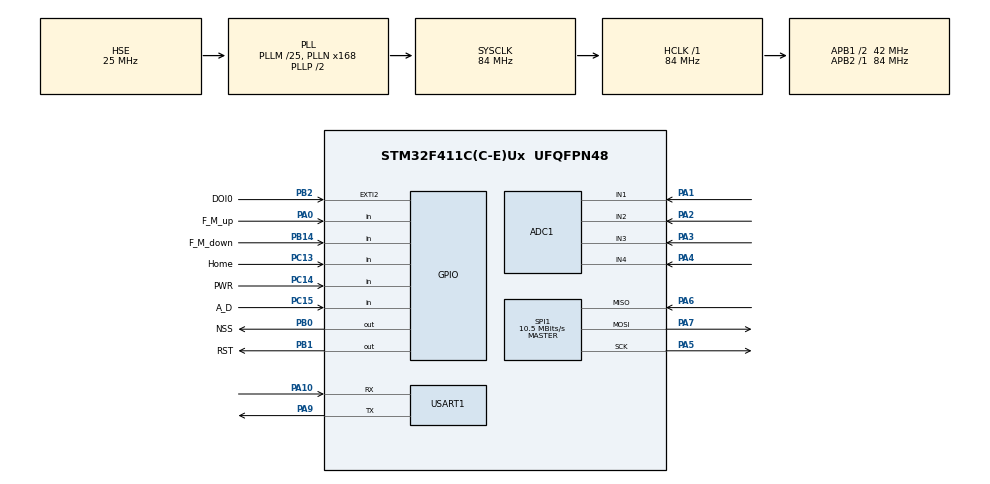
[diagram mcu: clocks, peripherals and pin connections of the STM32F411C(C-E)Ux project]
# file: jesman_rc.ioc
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ADC1.Channel-0\#ChannelRegularConversion=ADC_CHANNEL_1
ADC1.Channel-1\#ChannelRegularConversion=ADC_CHANNEL_2
ADC1.Channel-2\#ChannelRegularConversion=ADC_CHANNEL_3
ADC1.Channel-3\#ChannelRegularConversion=ADC_CHANNEL_4
ADC1.ContinuousConvMode=ENABLE
ADC1.DMAContinuousRequests=ENABLE
ADC1.EnableAnalogWatchDog=false
ADC1.InjNumberOfConversion=0
ADC1.NbrOfConversion=4
ADC1.NbrOfConversionFlag=1
ADC1.Rank-0\#ChannelRegularConversion=1
ADC1.Rank-1\#ChannelRegularConversion=2
ADC1.Rank-2\#ChannelRegularConversion=3
ADC1.Rank-3\#ChannelRegularConversion=4
ADC1.SamplingTime-0\#ChannelRegularConversion=ADC_SAMPLETIME_480CYCLES
ADC1.SamplingTime-1\#ChannelRegularConversion=ADC_SAMPLETIME_480CYCLES
ADC1.SamplingTime-2\#ChannelRegularConversion=ADC_SAMPLETIME_480CYCLES
ADC1.SamplingTime-3\#ChannelRegularConversion=ADC_SAMPLETIME_480CYCLES
ADC1.master=1
Dma.ADC1.0.Direction=DMA_PERIPH_TO_MEMORY
Dma.ADC1.0.FIFOMode=DMA_FIFOMODE_DISABLE
Dma.ADC1.0.Instance=DMA2_Stream0
Dma.ADC1.0.MemDataAlignment=DMA_MDATAALIGN_HALFWORD
Dma.ADC1.0.MemInc=DMA_MINC_ENABLE
Dma.ADC1.0.Mode=DMA_CIRCULAR
Dma.ADC1.0.PeriphDataAlignment=DMA_PDATAALIGN_HALFWORD
Dma.ADC1.0.PeriphInc=DMA_PINC_DISABLE
Dma.ADC1.0.Priority=DMA_PRIORITY_HIGH
Dma.Request0=ADC1
Mcu.Family=STM32F4
Mcu.Name=STM32F411C(C-E)Ux
Mcu.Package=UFQFPN48
NVIC.ADC_IRQn=true\:1\:0\:true\:false\:true\:true\:true\:true
NVIC.DMA2_Stream0_IRQn=true\:0\:0\:false\:false\:true\:false\:true\:true
NVIC.PriorityGroup=NVIC_PRIORITYGROUP_4
PA0-WKUP.GPIO_Label=F_M_up
PA0-WKUP.GPIO_PuPd=GPIO_PULLDOWN
PA0-WKUP.Signal=GPIO_Input
PA1.Signal=ADCx_IN1
PA10.Mode=Asynchronous
PA10.Signal=USART1_RX
PA13.Mode=Serial_Wire
PA13.Signal=SYS_JTMS-SWDIO
PA14.Mode=Serial_Wire
PA14.Signal=SYS_JTCK-SWCLK
PA2.Signal=ADCx_IN2
PA3.Signal=ADCx_IN3
PA4.Signal=ADCx_IN4
PA5.Mode=Full_Duplex_Master
PA5.Signal=SPI1_SCK
PA6.Mode=Full_Duplex_Master
PA6.Signal=SPI1_MISO
PA7.Mode=Full_Duplex_Master
PA7.Signal=SPI1_MOSI
PA9.Mode=Asynchronous
PA9.Signal=USART1_TX
PB0.GPIO_Label=NSS
PB0.PinState=GPIO_PIN_SET
PB0.Signal=GPIO_Output
PB1.GPIO_Label=RST
PB1.PinState=GPIO_PIN_SET
PB1.Signal=GPIO_Output
PB14.GPIO_Label=F_M_down
PB14.GPIO_PuPd=GPIO_PULLDOWN
PB14.Signal=GPIO_Input
PB2.GPIO_Label=DOI0
PB2.Signal=GPXTI2
PC13-ANTI_TAMP.GPIO_Label=Home
PC13-ANTI_TAMP.GPIO_PuPd=GPIO_PULLDOWN
PC13-ANTI_TAMP.Signal=GPIO_Input
PC14-OSC32_IN.GPIO_Label=PWR
PC14-OSC32_IN.GPIO_PuPd=GPIO_PULLDOWN
PC14-OSC32_IN.Signal=GPIO_Input
PC15-OSC32_OUT.GPIO_Label=A_D
PC15-OSC32_OUT.GPIO_PuPd=GPIO_PULLDOWN
PC15-OSC32_OUT.Signal=GPIO_Input
PH0\ -\ OSC_IN.Mode=HSE-External-Oscillator
PH0\ -\ OSC_IN.Signal=RCC_OSC_IN
PH1\ -\ OSC_OUT.Mode=HSE-External-Oscillator
PH1\ -\ OSC_OUT.Signal=RCC_OSC_OUT
ProjectManager.HeapSize=0x200
ProjectManager.StackSize=0x400
ProjectManager.TargetToolchain=STM32CubeIDE
RCC.48MHZClocksFreq_Value=42000000
RCC.AHBFreq_Value=84000000
RCC.APB1CLKDivider=RCC_HCLK_DIV2
RCC.APB1Freq_Value=42000000
RCC.APB1TimFreq_Value=84000000
RCC.APB2Freq_Value=84000000
RCC.APB2TimFreq_Value=84000000
RCC.CortexFreq_Value=84000000
RCC.HCLKFreq_Value=84000000
RCC.HSE_VALUE=25000000
RCC.HSI_VALUE=16000000
RCC.LSE_VALUE=32768
RCC.PLLM=25
RCC.PLLN=168
RCC.PLLSourceVirtual=RCC_PLLSOURCE_HSE
RCC.SYSCLKFreq_VALUE=84000000
RCC.SYSCLKSource=RCC_SYSCLKSOURCE_PLLCLK
RCC.VCOOutputFreq_Value=168000000
SH.ADCx_IN1.0=ADC1_IN1,IN1
SH.ADCx_IN2.0=ADC1_IN2,IN2
SH.ADCx_IN3.0=ADC1_IN3,IN3
SH.ADCx_IN4.0=ADC1_IN4,IN4
SPI1.BaudRatePrescaler=SPI_BAUDRATEPRESCALER_8
SPI1.CRCCalculation=SPI_CRCCALCULATION_ENABLE
SPI1.CalculateBaudRate=10.5 MBits/s
SPI1.Direction=SPI_DIRECTION_2LINES
SPI1.Mode=SPI_MODE_MASTER
SPI1.VirtualType=VM_MASTER
USART1.VirtualMode=VM_ASYNC
board=custom

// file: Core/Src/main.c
/* USER CODE BEGIN Header */
/**
  ******************************************************************************
  * @file           : main.c
  * @brief          : Main program body
  ******************************************************************************
  * @attention
  *
  * Copyright (c) 2025 STMicroelectronics.
  * All rights reserved.
  *
  * This software is licensed under terms that can be found in the LICENSE file
  * in the root directory of this software component.
  * If no LICENSE file comes with this software, it is provided AS-IS.
  *
  ******************************************************************************
  */
/* USER CODE END Header */
#include "main.h"

/* USER CODE BEGIN Includes */
#include "joystick.h"
#include "joystick_cfg.h"
#include "calib_button.h"

/* USER CODE END Includes */

/* USER CODE BEGIN PD */
uint16_t JoyStick1_XY[2] = {0};
uint16_t JoyStick2_XY[2] = {0};

/* USER CODE END PD */

ADC_HandleTypeDef hadc1;
DMA_HandleTypeDef hdma_adc1;

SPI_HandleTypeDef hspi1;

//UART_HandleTypeDef huart1;

void SystemClock_Config(void);
static void MX_GPIO_Init(void);
static void MX_DMA_Init(void);
static void MX_SPI1_Init(void);
static void MX_ADC1_Init(void);
static void MX_USART1_UART_Init(void);

int main(void)
{

  /* MCU Configuration--------------------------------------------------------*/

  /* Reset of all peripherals, Initializes the Flash interface and the Systick. */
  HAL_Init();

  /* Configure the system clock */
  SystemClock_Config();

  /* Initialize all configured peripherals */
  MX_GPIO_Init();
  MX_DMA_Init();
  MX_SPI1_Init();
  MX_ADC1_Init();
  MX_USART1_UART_Init();
  JoyStick_Init(JOYSTICK_INST_1);
  JoyStick_Init(JOYSTICK_INST_2);
  Joystick_Calibrate();

  /* Infinite loop */
  while (1)
  {
	  calib_button_state();
	  JoyStick_Read(JOYSTICK_INST_1, JoyStick1_XY[2]);
	  JoyStick_Read(JOYSTICK_INST_2, JoyStick2_XY[2]);

	  sprintf(MSG1, "%d,%d\r\n", JoyStick1_XY[0], JoyStick1_XY[1]);
	  sprintf(MSG2, "%d,%d\r\n", JoyStick2_XY[0], JoyStick2_XY[1]);
	  HAL_UART_Transmit(&huart1, MSG1, sizeof(MSG1), 100);
	  HAL_Delay(100);

  }
}

void SystemClock_Config(void)
{
  RCC_OscInitTypeDef RCC_OscInitStruct = {0};
  RCC_ClkInitTypeDef RCC_ClkInitStruct = {0};

  /** Configure the main internal regulator output voltage
  */
  __HAL_RCC_PWR_CLK_ENABLE();
  __HAL_PWR_VOLTAGESCALING_CONFIG(PWR_REGULATOR_VOLTAGE_SCALE1);

  /** Initializes the RCC Oscillators according to the specified parameters
  * in the RCC_OscInitTypeDef structure.
  */
  RCC_OscInitStruct.OscillatorType = RCC_OSCILLATORTYPE_HSE;
  RCC_OscInitStruct.HSEState = RCC_HSE_ON;
  RCC_OscInitStruct.PLL.PLLState = RCC_PLL_ON;
  RCC_OscInitStruct.PLL.PLLSource = RCC_PLLSOURCE_HSE;
  RCC_OscInitStruct.PLL.PLLM = 25;
  RCC_OscInitStruct.PLL.PLLN = 168;
  RCC_OscInitStruct.PLL.PLLP = RCC_PLLP_DIV2;
  RCC_OscInitStruct.PLL.PLLQ = 4;
  if (HAL_RCC_OscConfig(&RCC_OscInitStruct) != HAL_OK)
  {
    Error_Handler();
  }

  /** Initializes the CPU, AHB and APB buses clocks
  */
  RCC_ClkInitStruct.ClockType = RCC_CLOCKTYPE_HCLK|RCC_CLOCKTYPE_SYSCLK
                              |RCC_CLOCKTYPE_PCLK1|RCC_CLOCKTYPE_PCLK2;
  RCC_ClkInitStruct.SYSCLKSource = RCC_SYSCLKSOURCE_PLLCLK;
  RCC_ClkInitStruct.AHBCLKDivider = RCC_SYSCLK_DIV1;
  RCC_ClkInitStruct.APB1CLKDivider = RCC_HCLK_DIV2;
  RCC_ClkInitStruct.APB2CLKDivider = RCC_HCLK_DIV1;

  if (HAL_RCC_ClockConfig(&RCC_ClkInitStruct, FLASH_LATENCY_2) != HAL_OK)
  {
    Error_Handler();
  }
}

/**
  * @brief ADC1 Initialization Function
  * @param None
  * @retval None
static void MX_ADC1_Init(void)
{

  //ADC_ChannelConfTypeDef sConfig = {0};

  /** Configure the global features of the ADC (Clock, Resolution, Data Alignment and number of conversion)
  hadc1.Instance = ADC1;
  hadc1.Init.ClockPrescaler = ADC_CLOCK_SYNC_PCLK_DIV4;
  hadc1.Init.Resolution = ADC_RESOLUTION_12B;
  hadc1.Init.ScanConvMode = ENABLE;
  hadc1.Init.ContinuousConvMode = ENABLE;
  hadc1.Init.DiscontinuousConvMode = DISABLE;
  hadc1.Init.ExternalTrigConvEdge = ADC_EXTERNALTRIGCONVEDGE_NONE;
  hadc1.Init.ExternalTrigConv = ADC_SOFTWARE_START;
  hadc1.Init.DataAlign = ADC_DATAALIGN_RIGHT;
  hadc1.Init.NbrOfConversion = 4;
  hadc1.Init.DMAContinuousRequests = ENABLE;
  hadc1.Init.EOCSelection = ADC_EOC_SINGLE_CONV;
  if (HAL_ADC_Init(&hadc1) != HAL_OK)
  {
    Error_Handler();
  }

  /** Configure for the selected ADC regular channel its corresponding rank in the sequencer and its sample time.
  sConfig.Channel = ADC_CHANNEL_1;
  sConfig.Rank = 1;
  sConfig.SamplingTime = ADC_SAMPLETIME_480CYCLES;
  if (HAL_ADC_ConfigChannel(&hadc1, &sConfig) != HAL_OK)
  {
    Error_Handler();
  }

  /** Configure for the selected ADC regular channel its corresponding rank in the sequencer and its sample time.
  sConfig.Channel = ADC_CHANNEL_2;
  sConfig.Rank = 2;
  if (HAL_ADC_ConfigChannel(&hadc1, &sConfig) != HAL_OK)
  {
    Error_Handler();
  }

  /** Configure for the selected ADC regular channel its corresponding rank in the sequencer and its sample time.
  sConfig.Channel = ADC_CHANNEL_3;
  sConfig.Rank = 3;
  if (HAL_ADC_ConfigChannel(&hadc1, &sConfig) != HAL_OK)
  {
    Error_Handler();
  }

  /** Configure for the selected ADC regular channel its corresponding rank in the sequencer and its sample time.
  sConfig.Channel = ADC_CHANNEL_4;
  sConfig.Rank = 4;
  if (HAL_ADC_ConfigChannel(&hadc1, &sConfig) != HAL_OK)
  {
    Error_Handler();
  }
  /* USER CODE BEGIN ADC1_Init 2 */

  /* USER CODE END ADC1_Init 2

}
*/

static void MX_SPI1_Init(void)
{

  /* SPI1 parameter configuration*/
  hspi1.Instance = SPI1;
  hspi1.Init.Mode = SPI_MODE_MASTER;
  hspi1.Init.Direction = SPI_DIRECTION_2LINES;
  hspi1.Init.DataSize = SPI_DATASIZE_8BIT;
  hspi1.Init.CLKPolarity = SPI_POLARITY_LOW;
  hspi1.Init.CLKPhase = SPI_PHASE_1EDGE;
  hspi1.Init.NSS = SPI_NSS_SOFT;
  hspi1.Init.BaudRatePrescaler = SPI_BAUDRATEPRESCALER_8;
  hspi1.Init.FirstBit = SPI_FIRSTBIT_MSB;
  hspi1.Init.TIMode = SPI_TIMODE_DISABLE;
  hspi1.Init.CRCCalculation = SPI_CRCCALCULATION_ENABLE;
  hspi1.Init.CRCPolynomial = 10;
  if (HAL_SPI_Init(&hspi1) != HAL_OK)
  {
    Error_Handler();
  }

}

static void MX_USART1_UART_Init(void)
{

  huart1.Instance = USART1;
  huart1.Init.BaudRate = 115200;
  huart1.Init.WordLength = UART_WORDLENGTH_8B;
  huart1.Init.StopBits = UART_STOPBITS_1;
  huart1.Init.Parity = UART_PARITY_NONE;
  huart1.Init.Mode = UART_MODE_TX_RX;
  huart1.Init.HwFlowCtl = UART_HWCONTROL_NONE;
  huart1.Init.OverSampling = UART_OVERSAMPLING_16;
  if (HAL_UART_Init(&huart1) != HAL_OK)
  {
    Error_Handler();
  }

}

static void MX_DMA_Init(void)
{

  /* DMA controller clock enable */
  __HAL_RCC_DMA2_CLK_ENABLE();

  /* DMA interrupt init */
  /* DMA2_Stream0_IRQn interrupt configuration */
  HAL_NVIC_SetPriority(DMA2_Stream0_IRQn, 0, 0);
  HAL_NVIC_EnableIRQ(DMA2_Stream0_IRQn);

}

static void MX_GPIO_Init(void)
{
  GPIO_InitTypeDef GPIO_InitStruct = {0};

  /* GPIO Ports Clock Enable */
  __HAL_RCC_GPIOC_CLK_ENABLE();
  __HAL_RCC_GPIOH_CLK_ENABLE();
  __HAL_RCC_GPIOA_CLK_ENABLE();
  __HAL_RCC_GPIOB_CLK_ENABLE();

  /*Configure GPIO pin Output Level */
  HAL_GPIO_WritePin(GPIOB, NSS_Pin|RST_Pin, GPIO_PIN_SET);

  /*Configure GPIO pins : Home_Pin PWR_Pin A_D_Pin */
  GPIO_InitStruct.Pin = Home_Pin|PWR_Pin|A_D_Pin;
  GPIO_InitStruct.Mode = GPIO_MODE_INPUT;
  GPIO_InitStruct.Pull = GPIO_PULLDOWN;
  HAL_GPIO_Init(GPIOC, &GPIO_InitStruct);

  /*Configure GPIO pin : F_M_up_Pin */
  GPIO_InitStruct.Pin = F_M_up_Pin;
  GPIO_InitStruct.Mode = GPIO_MODE_INPUT;
  GPIO_InitStruct.Pull = GPIO_PULLDOWN;
  HAL_GPIO_Init(F_M_up_GPIO_Port, &GPIO_InitStruct);

  /*Configure GPIO pins : NSS_Pin RST_Pin */
  GPIO_InitStruct.Pin = NSS_Pin|RST_Pin;
  GPIO_InitStruct.Mode = GPIO_MODE_OUTPUT_PP;
  GPIO_InitStruct.Pull = GPIO_NOPULL;
  GPIO_InitStruct.Speed = GPIO_SPEED_FREQ_LOW;
  HAL_GPIO_Init(GPIOB, &GPIO_InitStruct);

  /*Configure GPIO pin : DOI0_Pin */
  GPIO_InitStruct.Pin = DOI0_Pin;
  GPIO_InitStruct.Mode = GPIO_MODE_IT_RISING;
  GPIO_InitStruct.Pull = GPIO_NOPULL;
  HAL_GPIO_Init(DOI0_GPIO_Port, &GPIO_InitStruct);

  /*Configure GPIO pin : F_M_down_Pin */
  GPIO_InitStruct.Pin = F_M_down_Pin;
  GPIO_InitStruct.Mode = GPIO_MODE_INPUT;
  GPIO_InitStruct.Pull = GPIO_PULLDOWN;
  HAL_GPIO_Init(F_M_down_GPIO_Port, &GPIO_InitStruct);

}

void Error_Handler(void)
{
  __disable_irq();
  while (1)
  {
  }
}
